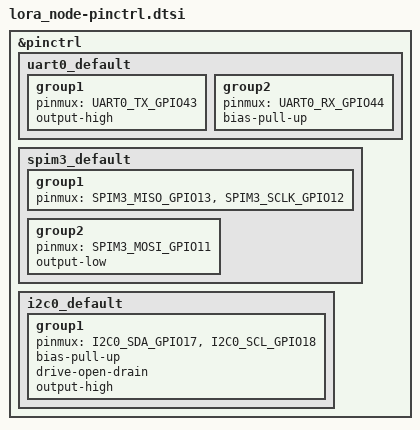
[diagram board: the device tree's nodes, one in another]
/*
 * Copyright 2022 Google LLC
 *
 * SPDX-License-Identifier: Apache-2.0
 */

#include <zephyr/dt-bindings/pinctrl/esp-pinctrl-common.h>
#include <zephyr/dt-bindings/pinctrl/esp32s3-pinctrl.h>
#include <zephyr/dt-bindings/pinctrl/esp32s3-gpio-sigmap.h>

&pinctrl {
	uart0_default: uart0_default {
		group1 {
			pinmux = <UART0_TX_GPIO43>;
			output-high;
		};

		group2 {
			pinmux = <UART0_RX_GPIO44>;
			bias-pull-up;
		};
	};

	spim3_default: spim3_default {
		group1 {
			pinmux = <SPIM3_MISO_GPIO13>,
				 <SPIM3_SCLK_GPIO12>;
		};
		group2 {
			pinmux = <SPIM3_MOSI_GPIO11>;
			output-low;
		};
	};

	i2c0_default: i2c0_default {
		group1 {
			pinmux =
					<I2C0_SDA_GPIO17>,
					<I2C0_SCL_GPIO18>;
			bias-pull-up;
			drive-open-drain;
			output-high;
		};
	};
};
